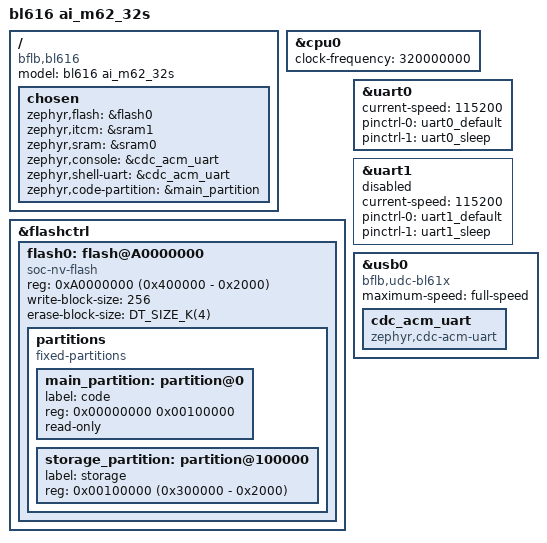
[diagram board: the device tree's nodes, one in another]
/*
 * Copyright (c) 2024 MASSDRIVER EI (massdriver.space)
 * SPDX-License-Identifier: Apache-2.0
 */

/dts-v1/;

#include <bouffalolab/bl616.dtsi>
#include <zephyr/dt-bindings/gpio/gpio.h>
#include <zephyr/dt-bindings/input/input-event-codes.h>
#include "ai_m62_32s-pinctrl.dtsi"

/ {
	model = "bl616 ai_m62_32s";
	compatible = "bflb,bl616";

	chosen {
		zephyr,flash = &flash0;
		zephyr,itcm = &sram1;
		zephyr,sram = &sram0;
		//zephyr,log-uart = &uart0;
		zephyr,console = &cdc_acm_uart;
		zephyr,shell-uart = &cdc_acm_uart;
		zephyr,code-partition = &main_partition;
	};

};

&cpu0 {
	clock-frequency = <320000000>;
};

&flashctrl {
	flash0: flash@A0000000 {
		compatible = "soc-nv-flash", "gd,25LQ32D";
		reg = <0xA0000000 (0x400000 - 0x2000)>;
		write-block-size = <256>;
		erase-block-size = <DT_SIZE_K(4)>;
		/* jedec-id = [c8 60 16]; */

		partitions {
			compatible = "fixed-partitions";
			#address-cells = <1>;
			#size-cells = <1>;

			main_partition: partition@0 {
				label = "code";
				reg = <0x00000000 0x00100000>;
				read-only;
			};

			storage_partition: partition@100000 {
				label = "storage";
				reg = <0x00100000 (0x300000 - 0x2000)>;
			};
		};
	};
};

&uart0 {
	status = "okay";
	current-speed = <115200>;

	pinctrl-0 = <&uart0_default>;
	pinctrl-1 = <&uart0_sleep>;
	pinctrl-names = "default", "sleep";
};

&uart1 {
	status = "disabled";
	current-speed = <115200>;

	pinctrl-0 = <&uart1_default>;
	pinctrl-1 = <&uart1_sleep>;
	pinctrl-names = "default", "sleep";
};

zephyr_udc0: &usb0 {
	compatible = "bflb,udc-bl61x";
	status = "okay";
	maximum-speed = "full-speed";

	cdc_acm_uart: cdc_acm_uart {
		compatible = "zephyr,cdc-acm-uart";
	};
};
